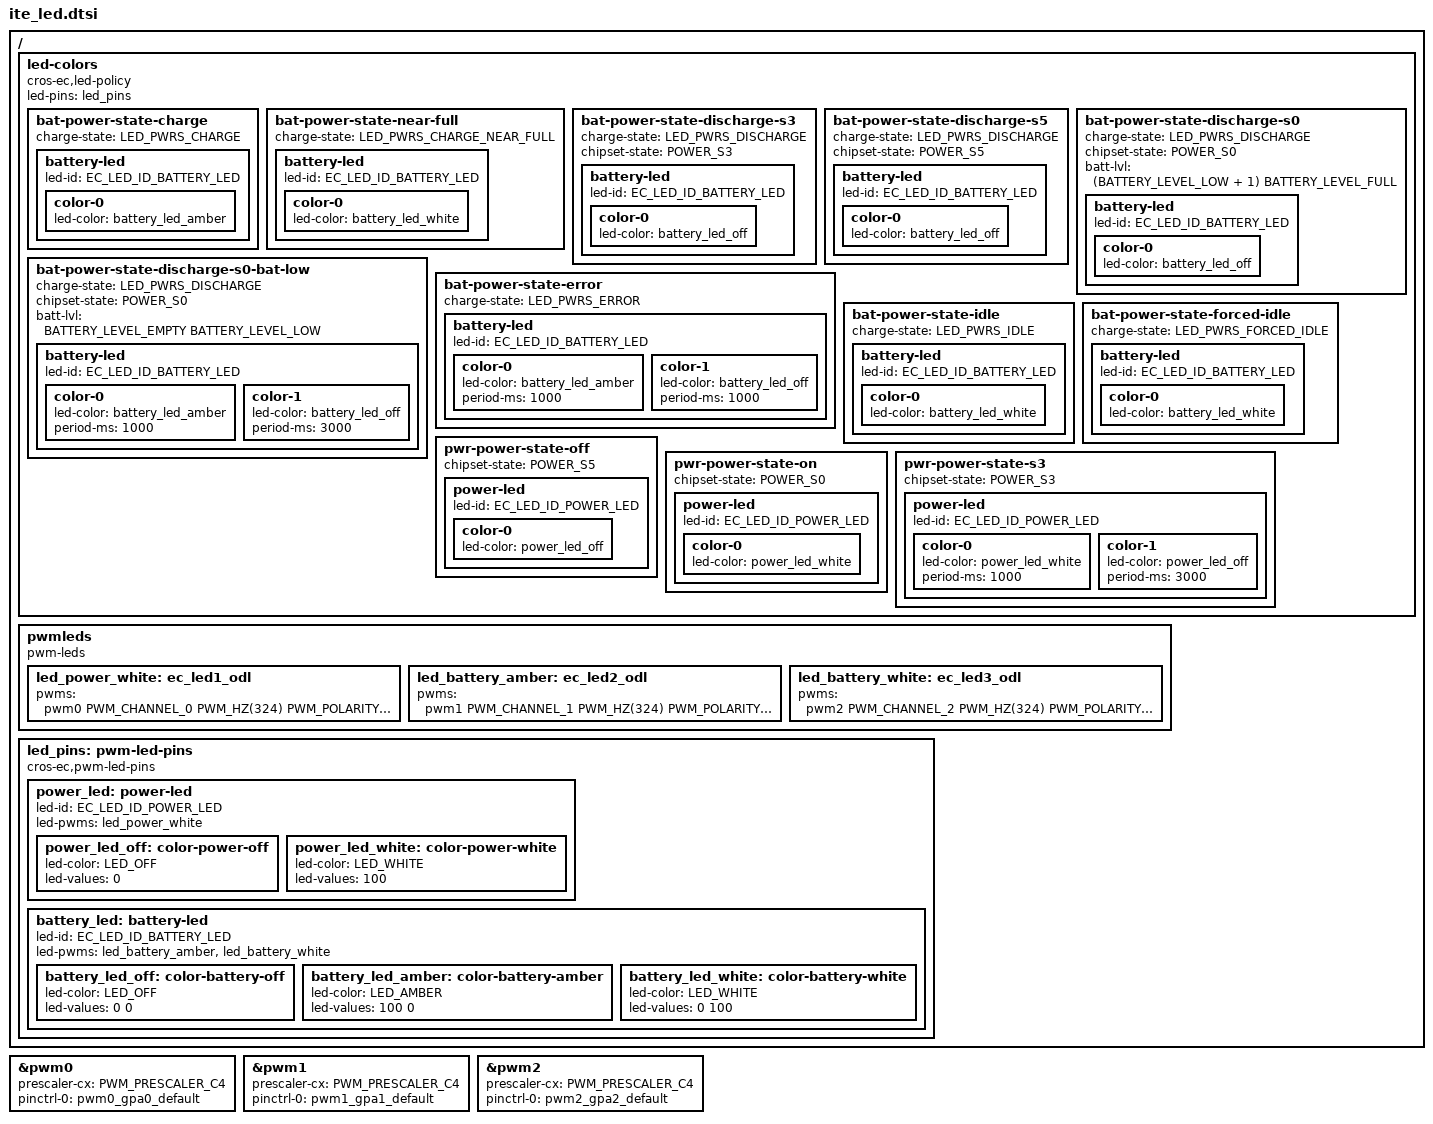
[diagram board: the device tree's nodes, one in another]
/* Copyright 2022 The ChromiumOS Authors
 * Use of this source code is governed by a BSD-style license that can be
 * found in the LICENSE file.
 */
#include <dt-bindings/battery.h>

/ {
	led-colors {
		compatible = "cros-ec,led-policy";
		led-pins = <&led_pins>;

		bat-power-state-charge {
			charge-state = "LED_PWRS_CHARGE";

			battery-led {
				led-id = "EC_LED_ID_BATTERY_LED";

				color-0 {
					led-color = <&battery_led_amber>;
				};
			};
		};

		bat-power-state-near-full {
			charge-state = "LED_PWRS_CHARGE_NEAR_FULL";

			battery-led {
				led-id = "EC_LED_ID_BATTERY_LED";

				color-0 {
					led-color = <&battery_led_white>;
				};
			};
		};

		bat-power-state-discharge-s3 {
			charge-state = "LED_PWRS_DISCHARGE";
			chipset-state = "POWER_S3";

			battery-led {
				led-id = "EC_LED_ID_BATTERY_LED";

				color-0 {
					led-color = <&battery_led_off>;
				};
			};
		};

		bat-power-state-discharge-s5 {
			charge-state = "LED_PWRS_DISCHARGE";
			chipset-state = "POWER_S5";

			battery-led {
				led-id = "EC_LED_ID_BATTERY_LED";

				color-0 {
					led-color = <&battery_led_off>;
				};
			};
		};

		bat-power-state-discharge-s0 {
			charge-state = "LED_PWRS_DISCHARGE";
			chipset-state = "POWER_S0";
			batt-lvl = <(BATTERY_LEVEL_LOW + 1) BATTERY_LEVEL_FULL>;

			battery-led {
				led-id = "EC_LED_ID_BATTERY_LED";

				color-0 {
					led-color = <&battery_led_off>;
				};
			};
		};

		bat-power-state-discharge-s0-bat-low {
			charge-state = "LED_PWRS_DISCHARGE";
			chipset-state = "POWER_S0";
			batt-lvl = <BATTERY_LEVEL_EMPTY BATTERY_LEVEL_LOW>;

			battery-led {
				led-id = "EC_LED_ID_BATTERY_LED";

				color-0 {
					led-color = <&battery_led_amber>;
					period-ms = <1000>;
				};

				color-1 {
					led-color = <&battery_led_off>;
					period-ms = <3000>;
				};
			};
		};

		bat-power-state-error {
			charge-state = "LED_PWRS_ERROR";

			battery-led {
				led-id = "EC_LED_ID_BATTERY_LED";

				color-0 {
					led-color = <&battery_led_amber>;
					period-ms = <1000>;
				};

				color-1 {
					led-color = <&battery_led_off>;
					period-ms = <1000>;
				};
			};
		};

		bat-power-state-idle {
			charge-state = "LED_PWRS_IDLE";

			battery-led {
				led-id = "EC_LED_ID_BATTERY_LED";

				color-0 {
					led-color = <&battery_led_white>;
				};
			};
		};

		bat-power-state-forced-idle {
			charge-state = "LED_PWRS_FORCED_IDLE";

			battery-led {
				led-id = "EC_LED_ID_BATTERY_LED";

				color-0 {
					led-color = <&battery_led_white>;
				};
			};
		};

		pwr-power-state-off {
			chipset-state = "POWER_S5";

			power-led {
				led-id = "EC_LED_ID_POWER_LED";
				color-0 {
					led-color = <&power_led_off>;
				};
			};
		};

		pwr-power-state-on {
			chipset-state = "POWER_S0";

			power-led {
				led-id = "EC_LED_ID_POWER_LED";

				color-0 {
					led-color = <&power_led_white>;
				};
			};
		};

		pwr-power-state-s3 {
			chipset-state = "POWER_S3";

			power-led {
				led-id = "EC_LED_ID_POWER_LED";

				color-0 {
					led-color = <&power_led_white>;
					period-ms = <1000>;
				};

				color-1 {
					led-color = <&power_led_off>;
					period-ms = <3000>;
				};
			};
		};
	};

	pwmleds {
		compatible = "pwm-leds";

		/* NOTE: &pwm number needs same with channel number */
		led_power_white: ec_led1_odl {
			pwms = <&pwm0 PWM_CHANNEL_0 PWM_HZ(324) PWM_POLARITY_INVERTED>;
		};
		led_battery_amber: ec_led2_odl {
			pwms = <&pwm1 PWM_CHANNEL_1 PWM_HZ(324) PWM_POLARITY_INVERTED>;
		};
		led_battery_white: ec_led3_odl {
			pwms = <&pwm2 PWM_CHANNEL_2 PWM_HZ(324) PWM_POLARITY_INVERTED>;
		};
	};

	led_pins: pwm-led-pins {
		compatible = "cros-ec,pwm-led-pins";

		power_led: power-led {
			led-id = "EC_LED_ID_POWER_LED";
			led-pwms = <&led_power_white>;

			power_led_off: color-power-off {
				led-color = "LED_OFF";
				led-values = <0>;
			};

			power_led_white: color-power-white {
				led-color = "LED_WHITE";
				led-values = <100>;
			};
		};

		battery_led: battery-led {
			led-id = "EC_LED_ID_BATTERY_LED";
			led-pwms = <&led_battery_amber &led_battery_white>;

			battery_led_off: color-battery-off {
				led-color = "LED_OFF";
				led-values = <0 0>;
			};

			battery_led_amber: color-battery-amber {
				led-color = "LED_AMBER";
				led-values = <100 0>;
			};

			battery_led_white: color-battery-white {
				led-color = "LED_WHITE";
				led-values = <0 100>;
			};
		};
	};
};

/* LED1 */
&pwm0 {
	status = "okay";
	prescaler-cx = <PWM_PRESCALER_C4>;
	pinctrl-0 = <&pwm0_gpa0_default>;
	pinctrl-names = "default";
};

/* LED2 */
&pwm1 {
	status = "okay";
	prescaler-cx = <PWM_PRESCALER_C4>;
	pinctrl-0 = <&pwm1_gpa1_default>;
	pinctrl-names = "default";
};

/* LED3 */
&pwm2 {
	status = "okay";
	prescaler-cx = <PWM_PRESCALER_C4>;
	pinctrl-0 = <&pwm2_gpa2_default>;
	pinctrl-names = "default";
};
